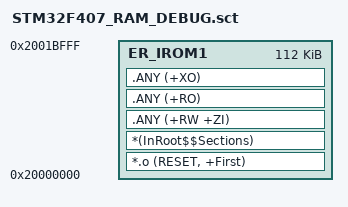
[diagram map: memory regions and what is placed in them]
; *************************************************************
; *** Scatter-Loading Description File generated by uVision ***
; *************************************************************

LR_IROM1 0x20000000 0x0001C000  {    ; load region size_region
  ER_IROM1 0x20000000 0x0001C000  {  ; load address = execution address
   *.o (RESET, +First)
   *(InRoot$$Sections)
   .ANY (+RW +ZI)
   .ANY (+RO)
   .ANY (+XO)
   
  }
  ;RW_IRAM2 0x2001C000 0x00004000  {  ; RW data
   ;.ANY (+RW +ZI)
  ;}
}

